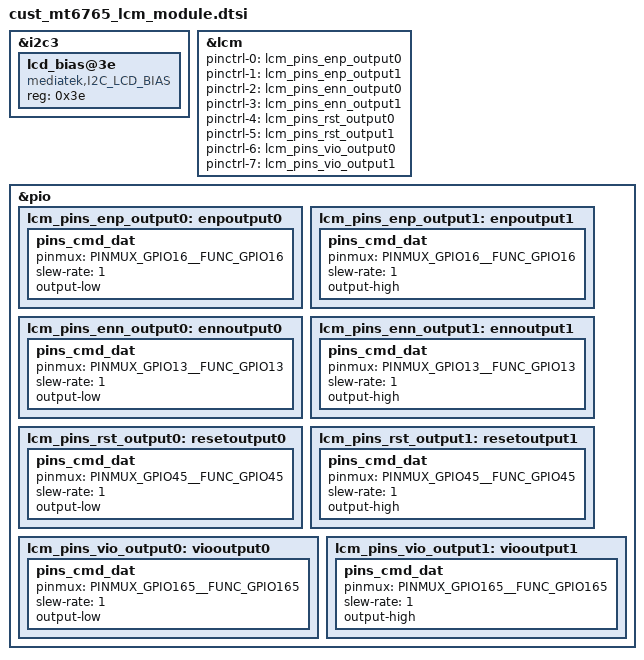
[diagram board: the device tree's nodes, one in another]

/*
 * Copyright (c) 2019 MediaTek Inc.
 * SPDX-License-Identifier: GPL-2.0+
 */

/* display start */
&i2c3 {
	lcd_bias@3e {
		compatible = "mediatek,I2C_LCD_BIAS";
		reg = <0x3e>;
		status = "okay";
	};
};

/*LCM start*/
&lcm {
	pinctrl-names = "state_enp_output0","state_enp_output1", "state_enn_output0",
		"state_enn_output1", "state_reset_output0", "state_reset_output1",
        "state_vio_output0", "state_vio_output1";
	pinctrl-0 = <&lcm_pins_enp_output0>;
	pinctrl-1 = <&lcm_pins_enp_output1>;
	pinctrl-2 = <&lcm_pins_enn_output0>;
	pinctrl-3 = <&lcm_pins_enn_output1>;
	pinctrl-4 = <&lcm_pins_rst_output0>;
	pinctrl-5 = <&lcm_pins_rst_output1>;
    pinctrl-6 = <&lcm_pins_vio_output0>;
	pinctrl-7 = <&lcm_pins_vio_output1>;
	status = "okay";
};

&pio {
	lcm_pins_enp_output0: enpoutput0 {
		pins_cmd_dat {
			pinmux = <PINMUX_GPIO16__FUNC_GPIO16>;
			slew-rate = <1>;
			output-low;
		};
	};
	lcm_pins_enp_output1: enpoutput1 {
		pins_cmd_dat {
			pinmux = <PINMUX_GPIO16__FUNC_GPIO16>;
			slew-rate = <1>;
			output-high;
		};
	};
	lcm_pins_enn_output0: ennoutput0 {
		pins_cmd_dat {
			pinmux = <PINMUX_GPIO13__FUNC_GPIO13>;
			slew-rate = <1>;
			output-low;
		};
	};
	lcm_pins_enn_output1: ennoutput1 {
		pins_cmd_dat {
			pinmux = <PINMUX_GPIO13__FUNC_GPIO13>;
			slew-rate = <1>;
			output-high;
		};
	};
	lcm_pins_rst_output0: resetoutput0 {
		pins_cmd_dat {
			pinmux = <PINMUX_GPIO45__FUNC_GPIO45>;
			slew-rate = <1>;
			output-low;
		};
	};
	lcm_pins_rst_output1: resetoutput1 {
		pins_cmd_dat {
			pinmux = <PINMUX_GPIO45__FUNC_GPIO45>;
			slew-rate = <1>;
			output-high;
		};
	};
    lcm_pins_vio_output0: viooutput0 {
		pins_cmd_dat {
			pinmux = <PINMUX_GPIO165__FUNC_GPIO165>;
			slew-rate = <1>;
			output-low;
		};
	};
	lcm_pins_vio_output1: viooutput1 {
		pins_cmd_dat {
			pinmux = <PINMUX_GPIO165__FUNC_GPIO165>;
			slew-rate = <1>;
			output-high;
		};
	};
};
/* LCM end */
/* display end */
